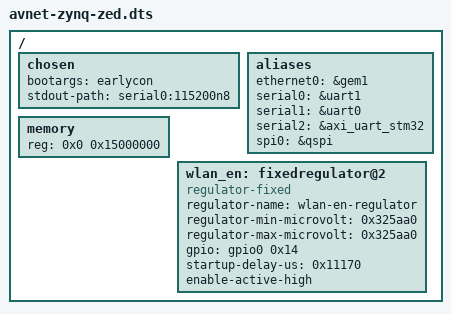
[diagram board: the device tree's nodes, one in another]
/*
 * CAUTION: This file is automatically generated by Xilinx.
 * Version:  
 * Today is: Wed Jan 15 12:55:47 2020
 */


/dts-v1/;
/include/ "zynq-7000.dtsi"
/include/ "zedboard.dtsi"
/include/ "pl.dtsi"
/include/ "pcw.dtsi"
/ {
	chosen {
		bootargs = "earlycon";
		stdout-path = "serial0:115200n8";
	};
	aliases {
		ethernet0 = &gem1;
		serial0 = &uart1;
		serial1 = &uart0;
		serial2 = &axi_uart_stm32;
		spi0 = &qspi;
	};
	memory {
		device_type = "memory";
		reg = <0x0 0x15000000>;
	};
wlan_en: fixedregulator@2 {
	compatible = "regulator-fixed";
	regulator-name = "wlan-en-regulator";
	regulator-min-microvolt = <0x325aa0>;
	regulator-max-microvolt = <0x325aa0>;
	gpio = <&gpio0 0x14 0x4>;
	startup-delay-us = <0x11170>;
	enable-active-high;
};
};
#include "system-user.dtsi"
